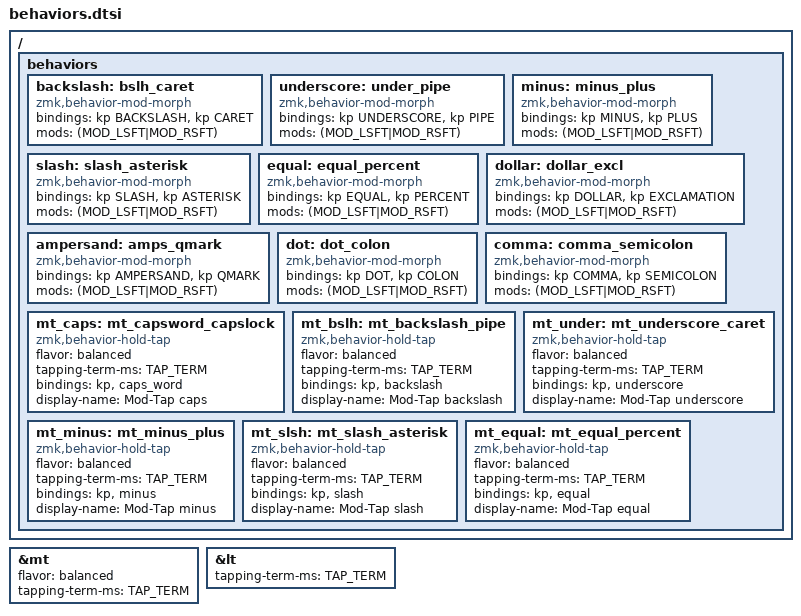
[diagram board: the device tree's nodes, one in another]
#define TAP_TERM 250

&mt {
    flavor = "balanced";
    tapping-term-ms = <TAP_TERM>;
};
&lt {
    tapping-term-ms = <TAP_TERM>;
};

/ {
    behaviors {
        // Custom keys
        backslash: bslh_caret {
            compatible = "zmk,behavior-mod-morph";
            #binding-cells = <0>;
            bindings = <&kp BACKSLASH>, <&kp CARET>;
            mods = <(MOD_LSFT|MOD_RSFT)>;
        };
        underscore: under_pipe {
            compatible = "zmk,behavior-mod-morph";
            #binding-cells = <0>;
            bindings = <&kp UNDERSCORE>, <&kp PIPE>;
            mods = <(MOD_LSFT|MOD_RSFT)>;
        };
        minus: minus_plus {
            compatible = "zmk,behavior-mod-morph";
            #binding-cells = <0>;
            bindings = <&kp MINUS>, <&kp PLUS>;
            mods = <(MOD_LSFT|MOD_RSFT)>;
        };
        slash: slash_asterisk {
            compatible = "zmk,behavior-mod-morph";
            #binding-cells = <0>;
            bindings = <&kp SLASH>, <&kp ASTERISK>;
            mods = <(MOD_LSFT|MOD_RSFT)>;
        };
        equal: equal_percent {
            compatible = "zmk,behavior-mod-morph";
            #binding-cells = <0>;
            bindings = <&kp EQUAL>, <&kp PERCENT>;
            mods = <(MOD_LSFT|MOD_RSFT)>;
        };
        dollar: dollar_excl {
            compatible = "zmk,behavior-mod-morph";
            #binding-cells = <0>;
            bindings = <&kp DOLLAR>, <&kp EXCLAMATION>;
            mods = <(MOD_LSFT|MOD_RSFT)>;
        };
        ampersand: amps_qmark {
            compatible = "zmk,behavior-mod-morph";
            #binding-cells = <0>;
            bindings = <&kp AMPERSAND>, <&kp QMARK>;
            mods = <(MOD_LSFT|MOD_RSFT)>;
        };
        dot: dot_colon {
            compatible = "zmk,behavior-mod-morph";
            #binding-cells = <0>;
            bindings = <&kp DOT>, <&kp COLON>;
            mods = <(MOD_LSFT|MOD_RSFT)>;
        };
        comma: comma_semicolon {
            compatible = "zmk,behavior-mod-morph";
            #binding-cells = <0>;
            bindings = <&kp COMMA>, <&kp SEMICOLON>;
            mods = <(MOD_LSFT|MOD_RSFT)>;
        };
        // Custom Hold-Tap for custom keys
        mt_caps: mt_capsword_capslock {
            compatible = "zmk,behavior-hold-tap";
            #binding-cells = <2>;
            flavor = "balanced";
            tapping-term-ms = <TAP_TERM>;
            bindings = <&kp>, <&caps_word>;
            display-name = "Mod-Tap caps";
        };
        mt_bslh: mt_backslash_pipe {
            compatible = "zmk,behavior-hold-tap";
            #binding-cells = <2>;
            flavor = "balanced";
            tapping-term-ms = <TAP_TERM>;
            bindings = <&kp>, <&backslash>;
            display-name = "Mod-Tap backslash";
        };
        mt_under: mt_underscore_caret {
            compatible = "zmk,behavior-hold-tap";
            #binding-cells = <2>;
            flavor = "balanced";
            tapping-term-ms = <TAP_TERM>;
            bindings = <&kp>, <&underscore>;
            display-name = "Mod-Tap underscore";
        };
        mt_minus: mt_minus_plus {
            compatible = "zmk,behavior-hold-tap";
            #binding-cells = <2>;
            flavor = "balanced";
            tapping-term-ms = <TAP_TERM>;
            bindings = <&kp>, <&minus>;
            display-name = "Mod-Tap minus";
        };
        mt_slsh: mt_slash_asterisk {
            compatible = "zmk,behavior-hold-tap";
            #binding-cells = <2>;
            flavor = "balanced";
            tapping-term-ms = <TAP_TERM>;
            bindings = <&kp>, <&slash>;
            display-name = "Mod-Tap slash";
        };
        mt_equal: mt_equal_percent {
            compatible = "zmk,behavior-hold-tap";
            #binding-cells = <2>;
            flavor = "balanced";
            tapping-term-ms = <TAP_TERM>;
            bindings = <&kp>, <&equal>;
            display-name = "Mod-Tap equal";
        };
    };
};
